# NUC1xx_registers register map
File version: 0.1
CPU: 
Registers are 32-bit, read-write, reset 0x0 unless marked. A register's access mark holds for its fields unless they carry their own. Offsets are from the block's base; [hi:lo] are bit positions; lines under a group give offsets from that group; 'fields as' and 'values as' point back to an identical list.

## UART0 — Registers group
Base 0x40050000
0x00 UA_RBR ro reset not defined — Receive Buffer Register.
  [7:0] RBR read-modifies — Receive Buffer Register By reading this register, the UART will return an 8-bit data received from Rx pin (LSB first).
0x00 UA_THR reset not defined — Transmit Holding Register.
  [7:0] THR wo — Transmit Holding Register By writing to this register, the UART will send out an 8-bit data through the TX pin (LSB first).
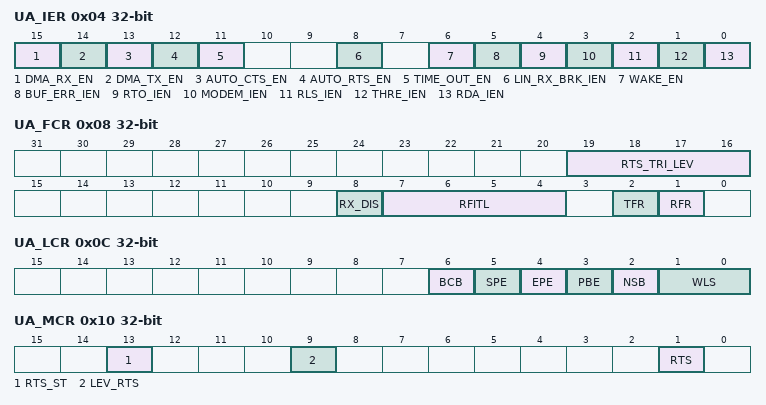
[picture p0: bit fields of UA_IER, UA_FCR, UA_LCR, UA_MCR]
0x04 UA_IER — Interrupt Enable Register.
  [15] DMA_RX_EN write-1-sets — Time-Out Counter Enable 1 = Enable RX DMA. 0 = Disable RX DMA.
  [14] DMA_TX_EN write-1-sets — TX DMA Enable 1 = Enable TX DMA. 0 = Disable TX DMA.
  [13] AUTO_CTS_EN write-1-sets — CTS Auto Flow Control Enable 1 = Enable CTS auto flow control. 0 = Disable CTS auto flow control. When CTS auto-flow is enabled, the UART will send data to external device when CTS input assert (UART will not send data to device until CTS is asserted).
  [12] AUTO_RTS_EN write-1-sets — RTS Auto Flow Control Enable 1 = Enable RTS auto flow control. 0 = Disable RTS auto flow control. When RTS auto-flow is enabled, if the number of bytes in the Rx FIFO equals the UA_FCR[RTS_Tri_Lev], the UART will de-assert RTS signal.
  [11] TIME_OUT_EN write-1-sets — Time-Out Counter Enable 1 = Enable Time-out counter. 0 = Disable Time-out counter.
  [8] LIN_RX_BRK_IEN write-1-sets — LIN RX Break Field Detected Interrupt Enable 0 = Mask off Lin bus Rx break filed interrupt. 1 = Enable Lin bus Rx break filed interrupt. Note: This field is used for LIN function mode.
  [6] WAKE_EN write-1-sets — Wake up CPU function enable 0 = Disable UART wake up CPU function 1 = Enable wake up function, when the system is in deep sleep mode, an external /CTS change will wake up CPU from deep sleep mode.
  [5] BUF_ERR_IEN write-1-sets — Buffer Error Interrupt Enable 0 = Mask off INT_Buf_ERR 1 = Enable INT_Buf_ERR
  [4] RTO_IEN write-1-sets — Rx Time out Interrupt Enable 0 = Mask off INT_TOUT 1 = Enable INT_TOUT.
  [3] MODEM_IEN write-1-sets — Modem Status Interrupt Enable 0 = Mask off INT_MODEM 1 = Enable INT_MODEM
  [2] RLS_IEN write-1-sets — Receive Line Status Interrupt Enable 0 = Mask off INT_RLS 1 = Enable INT_RLS
  [1] THRE_IEN write-1-sets — Transmit Holding Register Empty Interrupt Enable 0 = Mask off INT_THRE 1 = Enable INT_THRE
  [0] RDA_IEN write-1-sets — Receive Data Available Interrupt Enable. 0 = Mask off INT_RDA 1 = Enable INT_RDA
0x08 UA_FCR — FIFO Control Register.
  [19:16] RTS_TRI_LEV write-1-sets — RTS Trigger Level for Auto-flow Control Use(not available in UART2 channel) RTS_Tri_Lev Trigger Level (Bytes) 0000 01 0001 04 0010 08 0011 14 0100 30/14 (High Speed/Normal Speed) 0101 46/14 (High Speed/Normal Speed) 0110 62/14 (High Speed/Normal Speed) others 62/14 (High Speed/Normal Speed)
  [8] RX_DIS write-1-sets — Receiver Disable register The receiver is disabled or not (set 1 is disable receiver) 1 = Disable Receiver. 0 = Enable Receiver. Note: This field is used for RS-485 Normal Multi-drop mode. It should be programmed before UA_ALT_CSR [RS-485_NMM] is programmed.
  [7:4] RFITL write-1-sets — Rx FIFO Interrupt (INT_RDA) Trigger Level When the number of bytes in the receive FIFO equals the RFITL then the RDA_IF will be set (if IER [RDA_IEN] is enable, an interrupt will generated). RFITL INTR_RDA Trigger Level (Bytes) 0000 01 0001 04 0010 08 0011 14 0100 30/14 (High Speed/Normal Speed) 0101 46/14 (High Speed/Normal Speed) 0110 62/14 (High Speed/Normal Speed) others 62/14 (High Speed/Normal Speed)
  [2] TFR write-1-clears — Tx Field Software Reset When Tx_RST is set, all the bytes in the transmit FIFO and Tx internal state machine are cleared. 0 = Writing 0 to this bit has no effect. 1 = Writing 1 to this bit will reset the Tx internal state machine and pointers. Note: This bit will auto clear needs at least 3 UART engine clock cycles.
  [1] RFR write-1-clears — Rx Field Software Reset When Rx_RST is set, all the bytes in the transmit FIFO and Rx internal state machine are cleared. 0 = Writing 0 to this bit has no effect. 1 = Writing 1 to this bit will reset the Rx internal state machine and pointers. Note: This bit will auto clear needs at least 3 UART engine clock cycles.
0x0C UA_LCR — Line Control Register.
  [6] BCB write-1-sets — Break Control Bit When this bit is set to logic 1, the serial data output (TX) is forced to the Spacing State (logic 0). This bit acts only on TX and has no effect on the transmitter logic.
  [5] SPE write-1-sets — Stick Parity Enable 0 = Disable stick parity 1 = When bits PBE , EPE and SPE are set, the parity bit is transmitted and checked as cleared. When PBE and SPE are set and EPE is cleared, the parity bit is transmitted and checked as set.
  [4] EPE write-1-sets — Even Parity Enable 0 = Odd number of logic 1's are transmitted or checked in the data word and parity bits. 1 = Even number of logic 1's are transmitted or checked in the data word and parity bits. This bit has effect only when bit 3 (parity bit enable) is set.
  [3] PBE — Parity Bit Enable 0 = Parity bit is not generated (transmit data) or checked (receive data) during transfer. 1 = Parity bit is generated or checked between the "last data word bit" and "stop bit" of the serial data.
  [2] NSB write-1-sets — Number of "STOP bit" 0= One "STOP bit" is generated in the transmitted data 1= One and a half "STOP bit" is generated in the transmitted data when 5-bit word length is selected; Two "STOP bit" is generated when 6-, 7- and 8-bit word length is selected.
  [1:0] WLS write-1-sets — Word Length Select WLS[1:0] Character length 00 5 bits 01 6 bits 10 7 bits 11 8 bits
0x10 UA_MCR — Modem Control Register.
  [13] RTS_ST ro — RTS Pin State (not available in UART2 channel) This bit is the output pin status of RTS.
  [9] LEV_RTS write-1-sets — RTS Trigger Level (not available in UART2 channel) This bit can change the RTS trigger level. 0= low level triggered 1= high level triggered
  [1] RTS write-1-sets — RTS (Request-To-Send) Signal (not available in UART2 channel) 0: Drive RTS pin to logic 1 (If the LEV_RTS set to low level triggered). 1: Drive RTS pin to logic 0 (If the LEV_RTS set to low level triggered). 0: Drive RTS pin to logic 0 (If the LEV_RTS set to hihg level triggered). 1: Drive RTS pin to logic 1 (If the LEV_RTS set to high level triggered).
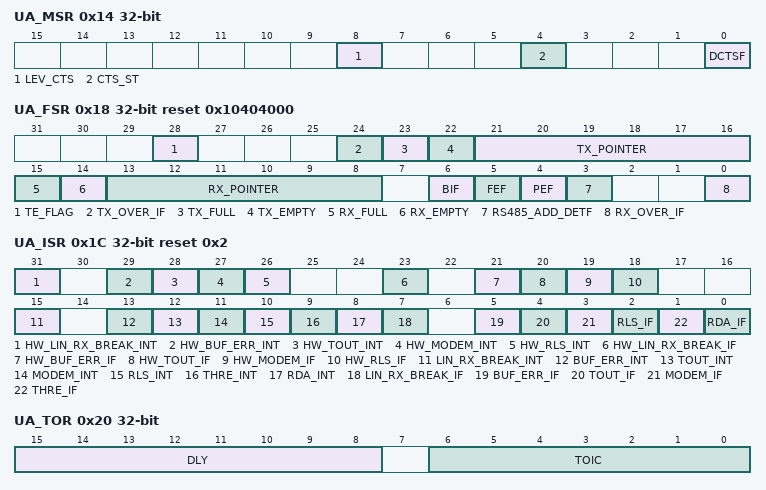
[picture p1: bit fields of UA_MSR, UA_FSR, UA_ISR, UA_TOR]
0x14 UA_MSR — Modem Status Register.
  [8] LEV_CTS write-1-sets — CTS Trigger Level (not available in UART2 channel) This bit can change the CTS trigger level. 0= low level triggered 1= high level triggered
  [4] CTS_ST ro — CTS Pin Status (not available in UART2 channel) This bit is the pin status of CTS.
  [0] DCTSF ro write-1-clears — Detect CTS State Change Flag (not available in UART2 channel) This bit is set whenever CTS input has change state, and it will generate Modem interrupt to CPU when UA_IER [Modem_IEN] is set to 1. NOTE: This bit is read only, but can be cleared by writing '1' to it.
0x18 UA_FSR reset 0x10404000 (reset mask 0xEFBFBFFF) — FIFO Status Register.
  [28] TE_FLAG ro — Transmitter Empty Flag (Read Only) Bit is set by hardware when Tx FIFO(UA_THR) is empty and the STOP bit of the last byte has been transmitted. Bit is cleared automatically when Tx FIFO is not empty or the last byte transmission has not completed. NOTE: This bit is read only.
  [24] TX_OVER_IF ro — Tx Overflow Error Interrupt Flag (Read Only) If Tx FIFO(UA_THR) is full, an additional write to UA_THR will cause this bit to logic 1. NOTE: This bit is read only, but can be cleared by writing '1' to it.
  [23] TX_FULL ro — Transmitter FIFO Full (Read Only) This bit indicates Tx FIFO full or not. This bit is set when Tx_Point is equal to 64/16(UART0/UART1), otherwise is cleared by hardware.
  [22] TX_EMPTY ro — Transmitter FIFO Empty (Read Only) This bit indicates Tx FIFO empty or not. When the last byte of Tx FIFO has been transferred to Transmitter Shift Register, hardware sets this bit high. It will be cleared when writing data into THR (Tx FIFO not empty).
  [21:16] TX_POINTER ro — TX FIFO Pointer (Read Only) This field indicates the Tx FIFO Buffer Pointer. When CPU write one byte into UA_THR, Tx_Pointer increases one. When one byte of Tx FIFO is transferred to Transmitter Shift Register, Tx_Pointer decreases one.
  [15] RX_FULL ro — Receiver FIFO Full (Read Only) This bit initiates Rx FIFO full or not. This bit is set when RX_POINTER is equal to 64/16(UART0/UART1), otherwise is cleared by hardware.
  [14] RX_EMPTY ro — Receiver FIFO Empty (Read Only) This bit initiate Rx FIFO empty or not. When the last byte of Rx FIFO has been read by CPU, hardware sets this bit high. It will be cleared when UART receives any new data.
  [13:8] RX_POINTER ro — Rx FIFO pointer (Read Only) This field indicates the Rx FIFO Buffer Pointer. When UART receives one byte from external device, Rx_Pointer increases one. When one byte of Rx FIFO is read by CPU, Rx_Pointer decreases one.
  [6] BIF ro — Break Interrupt Flag This bit is set to a logic 1 whenever the received data input(Rx) is held in the "spacing state" (logic 0) for longer than a full word transmission time (that is, the total time of "start bit" + data bits + parity + stop bits) and is reset whenever the CPU writes 1 to this bit. NOTE: This bit is read only, but can be cleared by writing '1' to it.
  [5] FEF ro — Framing Error Flag This bit is set to logic 1 whenever the received character does not have a valid "stop bit" (that is, the stop bit following the last data bit or parity bit is detected as a logic 0), and is reset whenever the CPU writes 1 to this bit. NOTE: This bit is read only, but can be cleared by writing '1' to it.
  [4] PEF ro — Parity Error Flag This bit is set to logic 1 whenever the received character does not have a valid "parity bit", and is reset whenever the CPU writes 1 to this bit. NOTE: This bit is read only, but can be cleared by writing '1' to it.
  [3] RS485_ADD_DETF ro — RS-485 Address Byte Detection Flag (Read Only) (Low Density Only) This bit is set to logic 1 and set UA_ALT_CSR [RS485_ADD_EN] whenever in RS-485 mode the receiver detect any address byte received address byte character (bit9 = 1) bit, and it is reset whenever the CPU writes 1 to this bit. NOTE: This field is used for RS-485 function mode. NOTE: This bit is read only, but can be cleared by writing '1' to it.
  [0] RX_OVER_IF ro — Rx overflow Error IF (Read Only) This bit is set when Rx FIFO overflow. If the number of bytes of received data is greater than Rx FIFO(UA_RBR) size, 64/16 bytes of (UA_RBR), this bit will be set. NOTE: This bit is read only, but can be cleared by writing '1' to it.
0x1C UA_ISR reset 0x2 (reset mask 0xFFFFFFFD) — Interrupt Status Register.
  [31] HW_LIN_RX_BREAK_INT — In DMA mode, LIN Bus Rx Break Field Detected Interrupt Indicator This bit is set if LIN_RX_BRK_IEN and HW_LIN_RX_BREAK_IF are both set to 1. 1 = The LIN RX Break interrupt is generated in DMA mode. 0 = No LIN RX Break interrupt is generated in DMA mode.
  [29] HW_BUF_ERR_INT — In DMA mode, Buffer Error Interrupt Indicator(INT_Buf_err) This bit is set if BUF_ERR_IEN and HW_BUF_ERR_IF are both set to 1. 1 = The buffer error interrupt is generated in DMA mode. 0 = No buffer error interrupt is generated in DMA mode.
  [28] HW_TOUT_INT — In DMA mode, Time Out Interrupt Indicator (INT_Tout) This bit is set if TOUT_IEN and HW_TOUT_IF are both set to 1. 1 = The Tout interrupt is generated in DMA mode. 0 = No Tout interrupt is generated in DMA mode.
  [27] HW_MODEM_INT — In DMA mode, MODEM Status Interrupt Indicator (INT_MOS)(not available in UART2 channel). This bit is set if MODEM_IEN and HW_MODEM_IF are both set to 1. 1 = The Modem interrupt is generated in DMA mode. 0 = No Modem interrupt is generated in DMA mode.
  [26] HW_RLS_INT — In DMA mode, Receive Line Status Interrupt Indicator (INT_RLS). This bit is set if RLS_IEN and HW_RLS_IF are both set to 1. 1 = The RLS interrupt is generated in DMA mode. 0 = No RLS interrupt is generated in DMA mode.
  [23] HW_LIN_RX_BREAK_IF — In DMA mode, LIN Bus Rx Break Field Detect Interrupt Flag This bit is set when Rx received LIN Break Field. If IER[LIN_RX_BRK_IEN] is enabled the LIN RX Break interrupt will be generated. NOTE: This bit is read only and user can write 1 to clear it.
  [21] HW_BUF_ERR_IF — In DMA mode, Buffer Error Interrupt Flag (Read Only) This bit is set when the Tx or Rx FIFO overflows (Tx_Over_IF or Rx_Over_IF is set). When Buf_Err_IF is set, the transfer maybe is not correct. If IER[Buf_Err_IEN] is enabled, the buffer error interrupt will be generated. NOTE: This bit is cleared when both Tx_Over_IF and Rx_Over_IF are cleared.
  [20] HW_TOUT_IF — In DMA mode, Time out Interrupt Flag (Read Only) This bit is set when the Rx FIFO is not empty and no activities occurres in the Rx FIFO and the time out counter equal to TOIC. If IER[Tout_IEN] is enabled, the Tout interrupt will be generated. NOTE: This bit is read only and user can read UA_RBR (Rx is in active) to clear it.
  [19] HW_MODEM_IF — In DMA mode, MODEM Interrupt Flag (Read Only) (not available in UART2 channel) This bit is set when the CTS pin has state change(DCTSF=1). if IER[Modem_IEN] is enabled, the Modem interrupt will be generated. NOTE: This bit is read only and reset to 0 when bit DCTSF is cleared by a write 1 on DCTSF.
  [18] HW_RLS_IF — In DMA mode, Receive Line Status Flag (Read Only) This bit is set when the Rx receive data have parity error, framing error or break error (at least one of 3 bits, BIF, FEF and PEF, is set). If IER[RLS_IEN] is enabled, the RLS interrupt will be generated. NOTE: This bit is read only and reset to 0 when all bits of BIF, FEF and PEF are cleared.
  [15] LIN_RX_BREAK_INT rw-once — LIN Bus Rx Break Field Detected Interrupt Indicator This bit is set if LIN_RX_BRK_IEN and LIN_RX_BREAK_IF are both set to 1. 1 = The LIN RX Break interrupt is generated. 0 = No LIN RX Break interrupt is generated.
  [13] BUF_ERR_INT ro — Buffer Error Interrupt Indicator (INT_Buf_err) This bit is set if BUF_ERR_IEN and BUF_ERR_IF are both set to 1. 1 = The buffer error interrupt is generated. 0 = No buffer error interrupt is generated.
  [12] TOUT_INT ro — Time Out Interrupt Indicator (INT_Tout) This bit is set if TOUT_IEN and TOUT_IF are both set to 1. 1 = The Tout interrupt is generated. 0 = No Tout interrupt is generated.
  [11] MODEM_INT ro — MODEM Status Interrupt Indicator to (INT_MOS). This bit is set if MODEM_IEN and MODEM_IF are both set to 1.. 1 = The Modem interrupt is generated. 0 = No Modem interrupt is generated.
  [10] RLS_INT ro — Receive Line Status Interrupt Indicator to (INT_RLS). This bit is set if RLS_IEN and RLS_IF are both set to 1. 1 = The RLS interrupt is generated. 0 = No RLS interrupt is generated.
  [9] THRE_INT ro — Transmit Holding Register Empty Interrupt Indicator (INT_THRE). This bit is set if THRE_IEN and THRE_IF are both set to 1. 1 = The THRE interrupt is generated. 0 = No THRE interrupt is generated.
  [8] RDA_INT ro — Receive Data Available Interrupt Indicator (INT_RDA). This bit is set if RDA_IEN and RDA_IF are both set to 1. 1 = The RDA interrupt is generated. 0 = No RDA interrupt is generated .
  [7] LIN_RX_BREAK_IF ro — LIN Bus RX Break Field Detected Flag This bit is set when RX received LIN Break Field. If UA_IER[LIN_RX_BRK_IEN] is enabled the LIN RX Break interrupt will be generated. NOTE: This bit is read only and user can write 1 to clear it.
  [5] BUF_ERR_IF ro — Buffer Error Interrupt Flag (Read Only) This bit is set when the TX or RX FIFO overflows (TX_Over_IF or RX_Over_IF is set). When BUF_ERR_IF is set, the transfer maybe is not correct. If UA_IER[BUF_ERR_IEN] is enabled, the buffer error interrupt will be generated. NOTE: This bit is cleared when both TX_OVER_IF and RX_OVER_IF are cleared.
  [4] TOUT_IF ro — Time Out Interrupt Flag (Read Only) This bit is set when the RX FIFO is not empty and no activities occurres in the RX FIFO and the time out counter equal to TOIC. If IER[Tout_IEN] is enabled, the Tout interrupt will be generated. NOTE: This bit is read only and user can read UA_RBR (Rx is in active) to clear it.
  [3] MODEM_IF ro — MODEM Interrupt Flag (Read Only) (not available in UART2 channel) This bit is set when the CTS pin has state change(DCTSF=1). if UA_IER[Modem_IEN] is enabled, the Modem interrupt will be generated. NOTE: This bit is read only and reset to 0 when bit DCTSF is cleared by a write 1 on DCTSF.
  [2] RLS_IF ro — Receive Line Interrupt Flag (Read Only). This bit is set when the Rx receive data have parity error, framing error or break error (at least one of 3 bits, BIF, FEF and PEF, is set). If IER[RLS_IEN] is enabled, the RLS interrupt will be generated. NOTE: This bit is read only and reset to 0 when all bits of BIF, FEF and PEF are cleared. NOTE: When in RS-485 function mode, this field include "receiver detect any address byte received address byte character (bit9 = 1') bit. "
  [1] THRE_IF ro — Transmit Holding Register Empty Interrupt Flag (Read Only). This bit is set when the last data of TX FIFO is transferred to Transmitter Shift Register. If UA_IER[THRE_IEN] is enabled, the THRE interrupt will be generated. NOTE: This bit is read only and it will be cleared when writing data into THR (TX FIFO not empty).
  [0] RDA_IF ro — Receive Data Available Interrupt Flag (Read Only). When the number of bytes in the Rx FIFO equals the RFITL then the RDA_IF will be set. If IER[RDA_IEN] is enabled, the RDA interrupt will be generated. NOTE: This bit is read only and it will be cleared when the number of unread bytes of Rx FIFO drops below the threshold level (RFITL).
0x20 UA_TOR — Time Out Register
  [15:8] DLY write-1-sets — TX Delay time value (Low Density Only) This field is use to programming the transfer delay time between the last stop bit and next start bit.
  [6:0] TOIC write-1-sets — Time Out Interrupt Comparator The time out counter resets and starts counting (the counting clock = baud rate) whenever the RX FIFO receives a new data word. Once the content of time out counter (TOUT_CNT) is equal to that of time out interrupt comparator (TOIC), a receiver time out interrupt (INTR_TOUT) is generated if UA_IER [RTO_IEN]. A new incoming data word or RX FIFO empty clears INTR_TOUT.
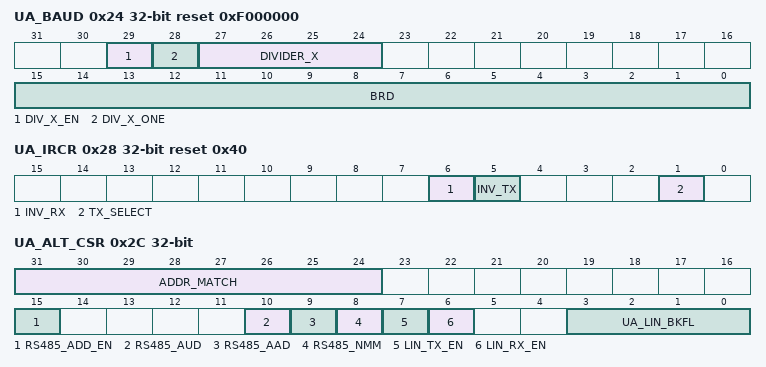
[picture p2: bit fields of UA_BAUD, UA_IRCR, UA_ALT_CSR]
0x24 UA_BAUD reset 0xF000000 (reset mask 0xF0FFFFFF) — Baud Rate Divisor Register
  [29] DIV_X_EN — Divider X Enable The BRD = Baud Rate Divider, and the baud rate equation is Baud Rate = Clock / [ M * (BRD + 2) ] ; The default value of M is 16. 0 = Disable divider X (the equation of M = 16) 1 = Enable divider X (the equation of M = X+1, but Divider_X[27:24 must > =8). NOTE: When in IrDA mode, this bit must disable. Mode DIV_X_EN DIV_X_ONE DIVIDER X BRD Baud rate equation 0 Disable 0 B A UART_CLK / [16 * (A+2)] 1 Enable 0 B A UART_CLK/[(B+1)*(A+2)],B must >= 8 2 Enable 1 Don't Care A UART_CLK / (A+2), A must >=3
  [28] DIV_X_ONE — Divider X equal 1 0 = Divider M = X (the equation of M = X+1, but Divider_X[27:24] must > =8) 1 = Divider M = 1 (the equation of M = 1, but BRD[15:0] must >=3). Mode DIV_X_EN DIV_X_ONE DIVIDER X BRD Baud rate equation 0 Disable 0 B A UART_CLK / [16 * (A+2)] 1 Enable 0 B A UART_CLK/[(B+1)*(A+2)],B must >= 8 2 Enable 1 Don't Care A UART_CLK / (A+2), A must >=3
  [27:24] DIVIDER_X — Divider X The baud rate divider M = X+1.
  [15:0] BRD write-1-sets — Baud Rate Divider The field indicated the baud rate divider
0x28 UA_IRCR reset 0x40 (reset mask 0xFFFFFFBF) — IrDA Control Register.
  [6] INV_RX write-0-sets — INV_RX 1= Inverse RX input signal 0= No inversion
  [5] INV_TX write-1-sets — INV_TX 1= Inverse TX output signal 0= No inversion
  [1] TX_SELECT write-1-sets — Enable IrDA Receiver 1: Enable IrDA transmitter 0: Enable IrDA receiver
0x2C UA_ALT_CSR — LIN Break Failed Count Register.
  [31:24] ADDR_MATCH write-1-sets — Address match value register (Low Density Only) This field contains the RS-485 address match values. Note: This field is used for RS-485 auto address detection mode.
  [15] RS485_ADD_EN write-1-sets — RS-485 Address Detection Enable (Low Density Only) 1 = Enable address detection mode. 0 = Disable address detection mode. Note: This field is used for RS485 any operation mode.
  [10] RS485_AUD write-1-sets — RS-485 Auto Direction Mode (AUD) (Low Density Only) 1 = Enable RS-485 Auto Direction Operation Mode (AUO). 0 = Disable RS-485 Auto Direction Operation Mode (AUO). Note:This field is used for RS-485 any operation mode. Note: It can be active with RS-485_AAD or RS485_NMM operation mode.
  [9] RS485_AAD write-1-sets — RS-485 Auto Address Detection Operation Mode (AAD) (Low Density Only) 1 = Enable RS-485 Auto Address Detection Operation Mode (AAD). 0 = Disable RS-485 Auto Address Detection Operation Mode (AAD). Note: It can't be active with RS485_NMM operation mode.
  [8] RS485_NMM write-1-sets — RS-485 Normal Multi-drop Operation Mode (NMM) (Low Density Only) 1 = Enable RS-485 Normal Multi-drop Operation Mode (NMM). 0 = Disable RS-485 Normal Multi-drop Operation Mode (NMM). Note: It can't be active with RS485_AAD operation mode.
  [7] LIN_TX_EN write-1-sets — LIN TX Break Mode Enable 1 = Enable LIN TX Break mode. 0 = Disable LIN TX Break mode. NOTE: When TX break field transfer operation finish, this will be cleared automatically.
  [6] LIN_RX_EN write-1-sets — LIN RX Enable 1 = Enable LIN RX mode. 0 = Disable LIN RX mode.
  [3:0] UA_LIN_BKFL write-1-sets — UART LIN Break Field Length This field indicates a 4-bit LIN TX break field count. NOTE: This break field length is UA_LIN_BKFL + 2
0x30 UA_FUN_SEL — Function Select Register.
  [1:0] FUN_SEL write-1-sets — Function Select Enable 00 = UART Function 01 = Enable LIN Function 10 = Enable IrDA Function 11 = Enable RS-485 Function (Low Density Only)

## UART1 — Registers group
Base 0x40150000
Registers as UART0; these are added or differ:
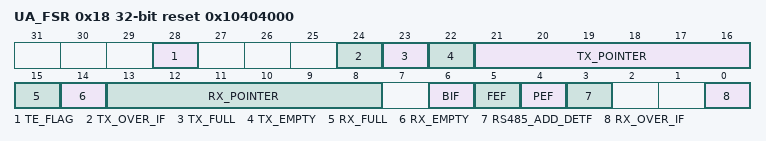
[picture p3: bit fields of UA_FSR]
0x18 UA_FSR reset 0x10404000 (reset mask 0xEFBFBFFF) — FIFO Status Register.
  fields as UART0.UA_FSR
